# ESP32-S31 register map
Vendor: ESPRESSIF SYSTEMS (SHANGHAI) CO., LTD.; Series: ESP32 S-Series; File version: 1
CPU: RV32IMAFC r0p0, little endian, no MPU, FPU, 0 interrupt priority bits
Address unit: 32 bits
Registers are 32-bit, read-write, reset 0x0 unless marked. A register's access mark holds for its fields unless they carry their own. Offsets are from the block's base; [hi:lo] are bit positions.

## GMAC (part 4 of 6) — GMAC Peripheral
Base 0x20350000
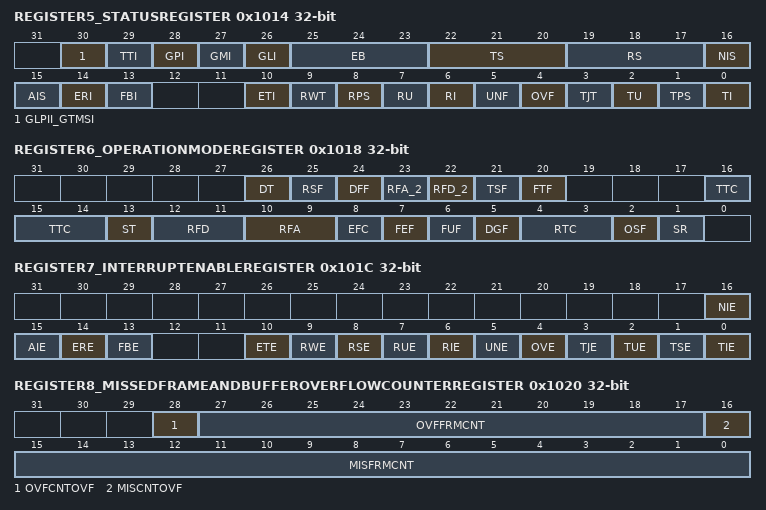
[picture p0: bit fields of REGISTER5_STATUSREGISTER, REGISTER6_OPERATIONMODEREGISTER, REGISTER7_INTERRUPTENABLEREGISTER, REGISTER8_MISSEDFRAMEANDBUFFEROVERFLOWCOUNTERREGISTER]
0x1014 REGISTER5_STATUSREGISTER access per field — The Software driver _application_ reads this register during interrupt service routine or polling to determine the status of the DMA
  [30] GLPII_GTMSI ro — GLPII: GMAC LPI Interrupt This bit indicates an interrupt event in the LPI logic of the MAC To reset this bit to 1'b0, the software must read the corresponding registers in the DWC_gmac to get the exact cause of the interrupt and clear its source Note: GLPII status is given only in Channel 0 DMA register and is applicable only when the Energy Efficient Ethernet feature is enabled Otherwise, this bit is reserved When this bit is high, the interrupt signal from the MAC _sbd_intr_o_ is high
  [29] TTI ro — Timestamp Trigger Interrupt This bit indicates an interrupt event in the Timestamp Generator block of the DWC_gmac The software must read the corresponding registers in the DWC_gmac to get the exact cause of the interrupt and clear its source to reset this bit to 1'b0 When this bit is high, the interrupt signal from the DWC_gmac subsystem _sbd_intr_o_ is high This bit is applicable only when the IEEE 1588 Timestamp feature is enabled Otherwise, this bit is reserved
  [28] GPI ro — GMAC PMT Interrupt This bit indicates an interrupt event in the PMT module of the DWC_gmac The software must read the PMT Control and Status Register in the MAC to get the exact cause of interrupt and clear its source to reset this bit to 1’b0 The interrupt signal from the DWC_gmac subsystem _sbd_intr_o_ is high when this bit is high This bit is applicable only when the Power Management feature is enabled Otherwise, this bit is reserved Note: The GPI and pmt_intr_o interrupts are generated in different clock domains
  [27] GMI ro — GMAC MMC Interrupt This bit reflects an interrupt event in the MMC module of the DWC_gmac The software must read the corresponding registers in the DWC_gmac to get the exact cause of the interrupt and clear the source of interrupt to make this bit as 1’b0 The interrupt signal from the DWC_gmac subsystem _sbd_intr_o_ is high when this bit is high This bit is applicable only when the MAC Management Counters _MMC_ are enabled Otherwise, this bit is reserved
  [26] GLI ro — GMAC Line Interface Interrupt When set, this bit reflects any of the following interrupt events in the DWC_gmac interfaces _if present and enabled in your configuration_: PCS _TBI, RTBI, or SGMII_: Link change or autonegotiation complete event SMII or RGMII: Link change event General Purpose Input Status _GPIS_: Any LL or LH event on the gpi_i input ports To identify the exact cause of the interrupt, the software must first read Bit 11 and Bits[2:0] of Register 14 _Interrupt Status Register_ and then to clear the source of interrupt _which also clears the GLI interrupt_, read any of the following corresponding registers: PCS _TBI, RTBI, or SGMII_: Register 49 _AN Status Register_ SMII or RGMII: Register 54 _SGMII/RGMII/SMII Control and Status Register_ General Purpose Input _GPI_: Register 56 _General Purpose IO Register_ The interrupt signal from the DWC_gmac subsystem _sbd_intr_o_ is high when this bit is high
  [25:23] EB ro — Error Bits This field indicates the type of error that caused a Bus Error, for example, error response on the AHB or AXI interface This field is valid only when Bit 13 _FBI_ is set This field does not generate an interrupt 0 0 0: Error during Rx DMA Write Data Transfer 0 1 1: Error during Tx DMA Read Data Transfer 1 0 0: Error during Rx DMA Descriptor Write Access 1 0 1: Error during Tx DMA Descriptor Write Access 1 1 0: Error during Rx DMA Descriptor Read Access 1 1 1: Error during Tx DMA Descriptor Read Access Note: 001 and 010 are reserved
  [22:20] TS ro — Transmit Process State This field indicates the Transmit DMA FSM state This field does not generate an interrupt 3’b000: Stopped: Reset or Stop Transmit Command issued 3’b001: Running: Fetching Transmit Transfer Descriptor 3’b010: Running: Waiting for status 3’b011: Running: Reading Data from host memory buffer and queuing it to transmit buffer _Tx FIFO_ 3’b100: TIME_STAMP write state 3’b101: Reserved for future use 3’b110: Suspended: Transmit Descriptor Unavailable or Transmit Buffer Underflow 3’b111: Running: Closing Transmit Descriptor
  [19:17] RS ro — Receive Process State This field indicates the Receive DMA FSM state This field does not generate an interrupt 3’b000: Stopped: Reset or Stop Receive Command issued 3’b001: Running: Fetching Receive Transfer Descriptor 3’b010: Reserved for future use 3’b011: Running: Waiting for receive packet 3’b100: Suspended: Receive Descriptor Unavailable 3’b101: Running: Closing Receive Descriptor 3’b110: TIME_STAMP write state 3’b111: Running: Transferring the receive packet data from receive buffer to host memory
  [16] NIS rw — Normal Interrupt Summary Normal Interrupt Summary bit value is the logical OR of the following bits when the corresponding interrupt bits are enabled in Register 7 _Interrupt Enable Register_: Register 5[0]: Transmit Interrupt Register 5[2]: Transmit Buffer Unavailable Register 5[6]: Receive Interrupt Register 5[14]: Early Receive Interrupt Only unmasked bits _interrupts for which interrupt enable is set in Register 7_ affect the Normal Interrupt Summary bit This is a sticky bit and must be cleared _by writing 1 to this bit_ each time a corresponding bit, which causes NIS to be set, is cleared
  [15] AIS rw — Abnormal Interrupt Summary Abnormal Interrupt Summary bit value is the logical OR of the following when the corresponding interrupt bits are enabled in Register 7 _Interrupt Enable Register_: Register 5[1]: Transmit Process Stopped Register 5[3]: Transmit Jabber Timeout Register 5[4]: Receive FIFO Overflow Register 5[5]: Transmit Underflow Register 5[7]: Receive Buffer Unavailable Register 5[8]: Receive Process Stopped Register 5[9]: Receive Watchdog Timeout Register 5[10]: Early Transmit Interrupt Register 5[13]: Fatal Bus Error Only unmasked bits affect the Abnormal Interrupt Summary bit This is a sticky bit and must be cleared _by writing 1 to this bit_ each time a corresponding bit, which causes AIS to be set, is cleared
  [14] ERI rw — Early Receive Interrupt This bit indicates that the DMA filled the first data buffer of the packet This bit is cleared when the software writes 1 to this bit or Bit 6 _RI_ of this register is set _whichever occurs earlier_
  [13] FBI rw — Fatal Bus Error Interrupt This bit indicates that a bus error occurred, as described in Bits [25:23] When this bit is set, the corresponding DMA engine disables all of its bus accesses 12:11 Reserved 00 RO
  [10] ETI rw — Early Transmit Interrupt This bit indicates that the frame to be transmitted is fully transferred to the MTL Transmit FIFO
  [9] RWT rw — Receive Watchdog Timeout When set, this bit indicates that the Receive Watchdog Timer expired while receiving the current frame and the current frame is truncated after the watchdog timeout
  [8] RPS rw — Receive Process Stopped This bit is asserted when the Receive Process enters the Stopped state
  [7] RU rw — Receive Buffer Unavailable This bit indicates that the host owns the Next Descriptor in the Receive List and the DMA cannot acquire it The Receive Process is suspended To resume processing Receive descriptors, the host should change the ownership of the descriptor and issue a Receive Poll Demand command If no Receive Poll Demand is issued, the Receive Process resumes when the next recognized incoming frame is received This bit is set only when the previous Receive Descriptor is owned by the DMA
  [6] RI rw — Receive Interrupt This bit indicates that the frame reception is complete When reception is complete, the Bit 31 of RDES1 _Disable Interrupt on Completion_ is reset in the last Descriptor, and the specific frame status information is updated in the descriptor The reception remains in the Running state
  [5] UNF rw — Transmit Underflow This bit indicates that the Transmit Buffer had an Underflow during frame transmission Transmission is suspended and an Underflow Error TDES0[1] is set
  [4] OVF rw — Receive Overflow This bit indicates that the Receive Buffer had an Overflow during frame reception If the partial frame is transferred to the application, the overflow status is set in RDES0[11]
  [3] TJT rw — Transmit Jabber Timeout This bit indicates that the Transmit Jabber Timer expired, which happens when the frame size exceeds 2,048 _10,240 bytes when the Jumbo frame is enabled_ When the Jabber Timeout occurs, the transmission process is aborted and placed in the Stopped state This causes the Transmit Jabber Timeout TDES0[14] flag to assert
  [2] TU rw — Transmit Buffer Unavailable This bit indicates that the host owns the Next Descriptor in the Transmit List and the DMA cannot acquire it Transmission is suspended Bits[22:20] explain the Transmit Process state transitions To resume processing Transmit descriptors, the host should change the ownership of the descriptor by setting TDES0[31] and then issue a Transmit Poll Demand command
  [1] TPS rw — Transmit Process Stopped This bit is set when the transmission is stopped
  [0] TI rw — Transmit Interrupt This bit indicates that the frame transmission is complete When transmission is complete, Bit 31 _OWN_ of TDES0 is reset, and the specific frame status information is updated in the descriptor
0x1018 REGISTER6_OPERATIONMODEREGISTER — Establishes the Receive and Transmit operating modes and command Note: This register is valid and present in the GMACMTL configuration
  [26] DT — Disable Dropping of TCP/IP Checksum Error Frames When this bit is set, the MAC does not drop the frames which only have errors detected by the Receive Checksum Offload engine Such frames do not have any errors _including FCS error_ in the Ethernet frame received by the MAC but have errors only in the encapsulated payload When this bit is reset, all error frames are dropped if the FEF bit is reset If the IPC Full Checksum Offload Engine _Type 2_ is disabled, this bit is reserved _RO with value 1'b0_
  [25] RSF — Receive Store and Forward When this bit is set, the MTL reads a frame from the Rx FIFO only after the complete frame has been written to it, ignoring the RTC bits When this bit is reset, the Rx FIFO operates in the cutthrough mode, subject to the threshold specified by the RTC bits
  [24] DFF — Disable Flushing of Received Frames When this bit is set, the Rx DMA does not flush any frames because of the unavailability of receive descriptors or buffers as it does normally when this bit is reset _See “Receive Process Suspended” on page 83_ This bit is reserved _and RO_ in the GMACMTL configuration
  [23] RFA_2 — MSB of Threshold for Activating Flow Control If the DWC_gmac is configured for an Rx FIFO size of 8 KB or more, this bit _when set_ provides additional threshold levels for activating the flow control in both half duplex and fullduplex modes This bit _as Most Significant Bit_, along with the RFA _Bits [10:9]_, gives the following thresholds for activating flow control: 100: Full minus 5 KB, that is, FULL — 5 KB 101: Full minus 6 KB, that is, FULL — 6 KB 110: Full minus 7 KB, that is, FULL — 7 KB 111: Reserved This bit is reserved _and RO_ if the Rx FIFO is 4 KB or less deep
  [22] RFD_2 — MSB of Threshold for Deactivating Flow Control If the DWC_gmac is configured for Rx FIFO size of 8 KB or more, this bit _when set_ provides additional threshold levels for deactivating the flow control in both halfduplex and fullduplex modes This bit _as Most Significant Bit_ along with the RFD _Bits [12:11]_ gives the following thresholds for deactivating flow control: 100: Full minus 5 KB, that is, FULL — 5 KB 101: Full minus 6 KB, that is, FULL — 6 KB 110: Full minus 7 KB, that is, FULL — 7 KB 111: Reserved This bit is reserved _and RO_ if the Rx FIFO is 4 KB or less deep
  [21] TSF — Transmit Store and Forward When this bit is set, transmission starts when a full frame resides in the MTL Transmit FIFO When this bit is set, the TTC values specified in Bits [16:14] are ignored This bit should be changed only when the transmission is stopped
  [20] FTF — Flush Transmit FIFO When this bit is set, the transmit FIFO controller logic is reset to its default values and thus all data in the Tx FIFO is lost or flushed This bit is cleared internally when the flushing operation is complete The Operation Mode register should not be written to until this bit is cleared The data which is already accepted by the MAC transmitter is not flushed It is scheduled for transmission and results in underflow and runt frame transmission Note: The flush operation is complete only when the Tx FIFO is emptied of its contents and all the pending Transmit Status of the transmitted frames are accepted by the host In order to complete this flush operation, the PHY transmit clock _clk_tx_i_ is required to be active 19:17 Reserved 000 RO
  [16:14] TTC — Transmit Threshold Control These bits control the threshold level of the MTL Transmit FIFO Transmission starts when the frame size within the MTL Transmit FIFO is larger than the threshold In addition, full frames with a length less than the threshold are also transmitted These bits are used only when Bit 21 _TSF_ is reset 000: 64 001: 128 010: 192 011: 256 100: 40 101: 32 110: 24 111: 16
  [13] ST — Start or Stop Transmission Command When this bit is set, transmission is placed in the Running state, and the DMA checks the Transmit List at the current position for a frame to be transmitted Descriptor acquisition is attempted either from the current position in the list, which is the Transmit List Base Address set by Register 4 _Transmit Descriptor List Address Register_, or from the position retained when transmission was stopped previously If the DMA does not own the current descriptor, transmission enters the Suspended state and Bit 2 _Transmit Buffer Unavailable_ of Register 5 _Status Register_ is set The Start Transmission command is effective only when transmission is stopped If the command is issued before setting Register 4 _Transmit Descriptor List Address Register_, then the DMA behavior is unpredictable When this bit is reset, the transmission process is placed in the Stopped state after completing the transmission of the current frame The Next Descriptor position in the Transmit List is saved, and it becomes the current position when transmission is restarted To change the list address, you need to program Register 4 _Transmit Descriptor List Address Register_ with a new value when this bit is reset The new value is considered when this bit is set again The stop transmission command is effective only when the transmission of the current frame is complete or the transmission is in the Suspended state Note: For information about how to pause the transmission, see “Stopping and Starting Transmission” on page 715
  [12:11] RFD — Threshold for Deactivating Flow Control _in halfduplex and fullduplex modes_ These bits control the threshold _Filllevel of Rx FIFO_ at which the flow control is deasserted after activation 00: Full minus 1 KB, that is, FULL — 1 KB 01: Full minus 2 KB, that is, FULL — 2 KB 10: Full minus 3 KB, that is, FULL — 3 KB 11: Full minus 4 KB, that is, FULL — 4 KB The deassertion is effective only after flow control is asserted If the Rx FIFO is 8 KB or more, an additional Bit _RFD_2_ is used for more threshold levels as described in Bit 22 These bits are reserved and readonly when the Rx FIFO depth is less than 4 KB Note: For proper flow control, the value programmed in the “RFD_2, RFD” fields should be equal to or more than the value programmed in the “RFA_2, RFA” fields
  [10:9] RFA — Threshold for Activating Flow Control _in halfduplex and fullduplex modes_ These bits control the threshold _Fill level of Rx FIFO_ at which the flow control is activated 00: Full minus 1 KB, that is, FULL—1KB 01: Full minus 2 KB, that is, FULL—2KB 10: Full minus 3 KB, that is, FULL—3KB 11: Full minus 4 KB, that is, FULL—4KB These values are applicable only to Rx FIFOs of 4 KB or more and when Bit 8 _EFC_ is set high If the Rx FIFO is 8 KB or more, an additional Bit _RFA_2_ is used for more threshold levels as described in Bit 23 These bits are reserved and readonly when the depth of Rx FIFO is less than 4 KB Note: When FIFO size is exactly 4 KB, although the DWC_gmac allows you to program the value of these bits to 11, the software should not program these bits to 2'b11 The value 2'b11 means flow control on FIFO empty condition
  [8] EFC — Enable HW Flow Control When this bit is set, the flow control signal operation based on the filllevel of Rx FIFO is enabled When reset, the flow control operation is disabled This bit is not used _reserved and always reset_ when the Rx FIFO is less than 4 KB
  [7] FEF — Forward Error Frames When this bit is reset, the Rx FIFO drops frames with error status _CRC error, collision error, GMII_ER, giant frame, watchdog timeout, or overflow_ However, if the start byte _write_ pointer of a frame is already transferred to the read controller side _in Threshold mode_, then the frame is not dropped In the GMACMTL configuration in which the Frame Length FIFO is also enabled during core configuration, the Rx FIFO drops the error frames if that frame's start byte is not transferred _output_ on the ARI bus When the FEF bit is set, all frames except runt error frames are forwarded to the DMA If the Bit 25 _RSF_ is set and the Rx FIFO overflows when a partial frame is written, then the frame is dropped irrespective of the FEF bit setting However, if the Bit 25 _RSF_ is reset and the Rx FIFO overflows when a partial frame is written, then a partial frame may be forwarded to the DMA Note: When FEF bit is reset, the giant frames are dropped if the giant frame status is given in Rx Status _in Table 86 or Table 823_ in the following configurations: The IP checksum engine _Type 1_ and full checksum offload engine _Type 2_ are not selected The advanced timestamp feature is not selected but the extended status is selected The extended status is available with the following features: L3L4 filter in GMACCORE or GMACMTL configurations Full checksum offload engine _Type 2_ with enhanced descriptor format in the GMACDMA, GMACAHB, or GMACAXI configurations
  [6] FUF — Forward Undersized Good Frames When set, the Rx FIFO forwards Undersized frames _that is, frames with no Error and length less than 64 bytes_ including padbytes and CRC When reset, the Rx FIFO drops all frames of less than 64 bytes, unless a frame is already transferred because of the lower value of Receive Threshold, for example, RTC = 01
  [5] DGF — Drop Giant Frames When set, the MAC drops the received giant frames in the Rx FIFO, that is, frames that are larger than the computed giant frame limit When reset, the MAC does not drop the giant frames in the Rx FIFO Note: This bit is available in the following configurations in which the giant frame status is not provided in Rx status and giant frames are not dropped by default: Configurations in which IP Checksum Offload _Type 1_ is selected in Rx Configurations in which the IPC Full Checksum Offload Engine _Type 2_ is selected in Rx with normal descriptor format Configurations in which the Advanced Timestamp feature is selected In all other configurations, this bit is not used _reserved and always reset_
  [4:3] RTC — Receive Threshold Control These two bits control the threshold level of the MTL Receive FIFO Transfer _request_ to DMA starts when the frame size within the MTL Receive FIFO is larger than the threshold In addition, full frames with length less than the threshold are automatically transferred The value of 11 is not applicable if the configured Receive FIFO size is 128 bytes These bits are valid only when the RSF bit is zero, and are ignored when the RSF bit is set to 1 00: 64 01: 32 10: 96 11: 128
  [2] OSF — Operate on Second Frame When this bit is set, it instructs the DMA to process the second frame of the Transmit data even before the status for the first frame is obtained
  [1] SR — Start or Stop Receive When this bit is set, the Receive process is placed in the Running state The DMA attempts to acquire the descriptor from the Receive list and processes the incoming frames The descriptor acquisition is attempted from the current position in the list, which is the address set by the Register 3 _Receive Descriptor List Address Register_ or the position retained when the Receive process was previously stopped If the DMA does not own the descriptor, reception is suspended and Bit 7 _Receive Buffer Unavailable_ of Register 5 _Status Register_ is set The Start Receive command is effective only when the reception has stopped If the command is issued before setting Register 3 _Receive Descriptor List Address Register_, the DMA behavior is unpredictable When this bit is cleared, the Rx DMA operation is stopped after the transfer of the current frame The next descriptor position in the Receive list is saved and becomes the current position after the Receive process is restarted The Stop Receive command is effective only when the Receive process is in either the Running _waiting for receive packet_ or in the Suspended state Note: For information about how to pause the transmission, see “Stopping and Starting Transmission” on page 715
0x101C REGISTER7_INTERRUPTENABLEREGISTER — Enables the interrupts reported by the Status Register
  [16] NIE — Normal Interrupt Summary Enable When this bit is set, normal interrupt summary is enabled When this bit is reset, normal interrupt summary is disabled This bit enables the following interrupts in Register 5 _Status Register_: Register 5[0]: Transmit Interrupt Register 5[2]: Transmit Buffer Unavailable Register 5[6]: Receive Interrupt Register 5[14]: Early Receive Interrupt
  [15] AIE — Abnormal Interrupt Summary Enable When this bit is set, abnormal interrupt summary is enabled When this bit is reset, the abnormal interrupt summary is disabled This bit enables the following interrupts in Register 5 _Status Register_: Register 5[1]: Transmit Process Stopped Register 5[3]: Transmit Jabber Timeout Register 5[4]: Receive Overflow Register 5[5]: Transmit Underflow Register 5[7]: Receive Buffer Unavailable Register 5[8]: Receive Process Stopped Register 5[9]: Receive Watchdog Timeout Register 5[10]: Early Transmit Interrupt Register 5[13]: Fatal Bus Error
  [14] ERE — Early Receive Interrupt Enable When this bit is set with Normal Interrupt Summary Enable _Bit 16_, the Early Receive Interrupt is enabled When this bit is reset, the Early Receive Interrupt is disabled
  [13] FBE — Fatal Bus Error Enable When this bit is set with Abnormal Interrupt Summary Enable _Bit 15_, the Fatal Bus Error Interrupt is enabled When this bit is reset, the Fatal Bus Error Enable Interrupt is disabled 12:11 Reserved 00 RO
  [10] ETE — Early Transmit Interrupt Enable When this bit is set with an Abnormal Interrupt Summary Enable _Bit 15_, the Early Transmit Interrupt is enabled When this bit is reset, the Early Transmit Interrupt is disabled
  [9] RWE — Receive Watchdog Timeout Enable When this bit is set with Abnormal Interrupt Summary Enable _Bit 15_, the Receive Watchdog Timeout Interrupt is enabled When this bit is reset, the Receive Watchdog Timeout Interrupt is disabled
  [8] RSE — Receive Stopped Enable When this bit is set with Abnormal Interrupt Summary Enable _Bit 15_, the Receive Stopped Interrupt is enabled When this bit is reset, the Receive Stopped Interrupt is disabled
  [7] RUE — Receive Buffer Unavailable Enable When this bit is set with Abnormal Interrupt Summary Enable _Bit 15_, the Receive Buffer Unavailable Interrupt is enabled When this bit is reset, the Receive Buffer Unavailable Interrupt is disabled
  [6] RIE — Receive Interrupt Enable When this bit is set with Normal Interrupt Summary Enable _Bit 16_, the Receive Interrupt is enabled When this bit is reset, the Receive Interrupt is disabled
  [5] UNE — Underflow Interrupt Enable When this bit is set with Abnormal Interrupt Summary Enable _Bit 15_, the Transmit Underflow Interrupt is enabled When this bit is reset, the Underflow Interrupt is disabled
  [4] OVE — Overflow Interrupt Enable When this bit is set with Abnormal Interrupt Summary Enable _Bit 15_, the Receive Overflow Interrupt is enabled When this bit is reset, the Overflow Interrupt is disabled
  [3] TJE — Transmit Jabber Timeout Enable When this bit is set with Abnormal Interrupt Summary Enable _Bit 15_, the Transmit Jabber Timeout Interrupt is enabled When this bit is reset, the Transmit Jabber Timeout Interrupt is disabled
  [2] TUE — Transmit Buffer Unavailable Enable When this bit is set with Normal Interrupt Summary Enable _Bit 16_, the Transmit Buffer Unavailable Interrupt is enabled When this bit is reset, the Transmit Buffer Unavailable Interrupt is disabled
  [1] TSE — Transmit Stopped Enable When this bit is set with Abnormal Interrupt Summary Enable _Bit 15_, the Transmission Stopped Interrupt is enabled When this bit is reset, the Transmission Stopped Interrupt is disabled
  [0] TIE — Transmit Interrupt Enable When this bit is set with Normal Interrupt Summary Enable _Bit 16_, the Transmit Interrupt is enabled When this bit is reset, the Transmit Interrupt is disabled The sbd_intr_o interrupt is generated as shown in Figure 61 It is asserted only when the TTI, GPI, GMI, GLI, or GLPII bit of the DMA Status register is asserted, or when the NIS or AIS Status bit is asserted and the corresponding Interrupt Enable bits _NIE or AIE_ are enabled
0x1020 REGISTER8_MISSEDFRAMEANDBUFFEROVERFLOWCOUNTERREGISTER — Contains the counters for discarded frames because no host Receive Descriptor was available or because of Receive FIFO Overflow
  [28] OVFCNTOVF — Overflow Bit for FIFO Overflow Counter This bit is set every time the Overflow Frame Counter _Bits[27:17]_ overflows, that is, the Rx FIFO overflows with the overflow frame counter at maximum value In such a scenario, the overflow frame counter is reset to allzeros and this bit indicates that the rollover happened
  [27:17] OVFFRMCNT — Overflow Frame Counter This field indicates the number of frames missed by the application This counter is incremented each time the MTL FIFO overflows The counter is cleared when this register is read with mci_be_i[2] at 1’b1
  [16] MISCNTOVF — Overflow Bit for Missed Frame Counter This bit is set every time Missed Frame Counter _Bits[15:0]_ overflows, that is, the DMA discards an incoming frame because of the Host Receive Buffer being unavailable with the missed frame counter at maximum value In such a scenario, the Missed frame counter is reset to allzeros and this bit indicates that the rollover happened
  [15:0] MISFRMCNT — Missed Frame Counter This field indicates the number of frames missed by the controller because of the Host Receive Buffer being unavailable This counter is incremented each time the DMA discards an incoming frame The counter is cleared when this register is read with mci_be_i[0] at 1’b1
0x1024 REGISTER9_RECEIVEINTERRUPTWATCHDOGTIMERREGISTER — Watchdog timeout for Receive Interrupt _RI_ from DMA
  [7:0] RIWT — RI Watchdog Timer Count This bit indicates the number of system clock cycles multiplied by 256 for which the watchdog timer is set The watchdog timer gets triggered with the programmed value after the Rx DMA completes the transfer of a frame for which the RI status bit is not set because of the setting in the corresponding descriptor RDES1[31] When the watchdog timer runs out, the RI bit is set and the timer is stopped The watchdog timer is reset when the RI bit is set high because of automatic setting of RI as per RDES1[31] of any received frame
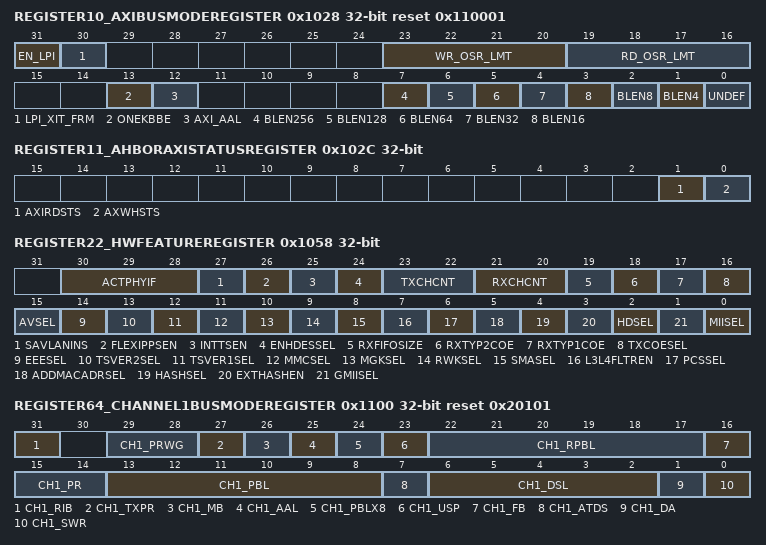
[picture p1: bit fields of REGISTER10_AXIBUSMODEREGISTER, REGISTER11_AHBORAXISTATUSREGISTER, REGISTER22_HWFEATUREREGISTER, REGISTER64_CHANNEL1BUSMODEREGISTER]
0x1028 REGISTER10_AXIBUSMODEREGISTER access per field reset 0x110001 — Controls AXI master behavior _mainly controls burst splitting and number of outstanding requests_
  [31] EN_LPI rw — Enable Low Power Interface _LPI_ When set to 1, this bit enables the LPI mode supported by the GMACAXI configuration and accepts the LPI request from the AXI System Clock controller When set to 0, this bit disables the LPI mode and always denies the LPI request from the AXI System Clock controller
  [30] LPI_XIT_FRM rw — Unlock on Magic Packet or Remote WakeUp Frame When set to 1, this bit enables the GMACAXI to come out of the LPI mode only when the magic packet or remote wakeup frame is received When set to 0, this bit enables the GMACAXI to come out of LPI mode when any frame is received 29:24 Reserved 00H RO
  [23:20] WR_OSR_LMT rw — AXI Maximum Write Outstanding Request Limit This value limits the maximum outstanding request on the AXI write interface Maximum outstanding requests = WR_OSR_LMT+1 Note: Bit 22 is reserved if AXI_GM_MAX_WR_REQUESTS = 4 Bit 23 bit is reserved if AXI_GM_MAX_WR_REQUESTS != 16
  [19:16] RD_OSR_LMT rw — AXI Maximum Read Outstanding Request Limit This value limits the maximum outstanding request on the AXI read interface Maximum outstanding requests = RD_OSR_LMT+1 Note: Bit 18 is reserved if AXI_GM_MAX_RD_REQUESTS = 4 Bit 19 is reserved if AXI_GM_MAX_RD_REQUESTS != 16 15:14 Reserved 00 RO
  [13] ONEKBBE rw — 1 KB Boundary Crossing Enable for the GMACAXI Master When set, the GMACAXI master performs burst transfers that do not cross 1 KB boundary When reset, the GMACAXI master performs burst transfers that do not cross 4 KB boundary
  [12] AXI_AAL ro — AddressAligned Beats This bit is readonly bit and reflects the Bit 25 _AAL_ of Register 0 _Bus Mode Register_ When this bit is set to 1, the GMACAXI performs addressaligned burst transfers on both read and write channels 11:8 Reserved 0H RO
  [7] BLEN256 rw — AXI Burst Length 256 When this bit is set to 1, the GMACAXI is allowed to select a burst length of 256 on the AXI master interface This bit is present only when the configuration parameter AXI_BL is set to 256 Otherwise, this bit is reserved and is readonly _RO_
  [6] BLEN128 rw — AXI Burst Length 128 When this bit is set to 1, the GMACAXI is allowed to select a burst length of 128 on the AXI master interface This bit is present only when the configuration parameter AXI_BL is set to 128 or more Otherwise, this bit is reserved and is readonly _RO_
  [5] BLEN64 rw — AXI Burst Length 64 When this bit is set to 1, the GMACAXI is allowed to select a burst length of 64 on the AXI master interface This bit is present only when the configuration parameter AXI_BL is set to 64 or more Otherwise, this bit is reserved and is readonly _RO_
  [4] BLEN32 rw — AXI Burst Length 32 When this bit is set to 1, the GMACAXI is allowed to select a burst length of 32 on the AXI master interface This bit is present only when the configuration parameter AXI_BL is set to 32 or more Otherwise, this bit is reserved and is readonly _RO_
  [3] BLEN16 rw — AXI Burst Length 16 When this bit is set to 1 or UNDEF is set to 1, the GMACAXI is allowed to select a burst length of 16 on the AXI master interface
  [2] BLEN8 rw — AXI Burst Length 8 When this bit is set to 1, the GMACAXI is allowed to select a burst length of 8 on the AXI master interface Setting this bit has no effect when UNDEF is set to 1
  [1] BLEN4 rw — AXI Burst Length 4 When this bit is set to 1, the GMACAXI is allowed to select a burst length of 4 on the AXI master interface Setting this bit has no effect when UNDEF is set to 1
  [0] UNDEF ro — AXI Undefined Burst Length This bit is readonly bit and indicates the complement _invert_ value of Bit 16 _FB_ in Register 0 _Bus Mode Register_ When this bit is set to 1, the GMACAXI is allowed to perform any burst length equal to or below the maximum allowed burst length programmed in Bits[7:3] When this bit is set to 0, the GMACAXI is allowed to perform only fixed burst lengths as indicated by BLEN256, BLEN128, BLEN64, BLEN32, BLEN16, BLEN8, or BLEN4, or a burst length of 1 If UNDEF is set and none of the BLEN bits is set, then GMACAXI is allowed to perform a burst length of 16
0x102C REGISTER11_AHBORAXISTATUSREGISTER ro — Gives the idle status of the AHB master interface in the GMACAHB configuration Gives the idle status of the AXI master's read or write channel in the GMACAXI configuration
  [1] AXIRDSTS — AXI Master Read Channel Status When high, it indicates that AXI master's read channel is active and transferring data
  [0] AXWHSTS — AXI Master Write Channel or AHB Master Status When high, it indicates that AXI master's write channel is active and transferring data in the GMACAXI configuration In the GMACAHB configuration, it indicates that the AHB master interface FSMs are in the nonidle state
0x1048 REGISTER18_CURRENTHOSTTRANSMITDESCRIPTORREGISTER ro — Points to the start of current Transmit Descriptor read by the DMA
  [31:0] CURTDESAPTR — Host Transmit Descriptor Address Pointer
0x104C REGISTER19_CURRENTHOSTRECEIVEDESCRIPTORREGISTER ro — Points to the start of current Receive Descriptor read by the DMA
  [31:0] CURRDESAPTR — Host Receive Descriptor Address Pointer
0x1050 REGISTER20_CURRENTHOSTTRANSMITBUFFERADDRESSREGISTER ro — Points to the current Transmit Buffer address read by the DMA
  [31:0] CURTBUFAPTR — Host Transmit Buffer Address Pointer
0x1054 REGISTER21_CURRENTHOSTRECEIVEBUFFERADDRESSREGISTER ro — Points to the current Receive Buffer address read by the DMA
  [31:0] CURRBUFAPTR — Host Receive Buffer Address Pointer
0x1058 REGISTER22_HWFEATUREREGISTER ro — Indicates the presence of the optional features of the core
  [30:28] ACTPHYIF — Active or selected PHY interface When you have multiple PHY interfaces in your configuration, this field indicates the sampled value of phy_intf_sel_i during reset deassertion 000: GMII or MII 001: RGMII 010: SGMII 011: TBI 100: RMII 101: RTBI 110: SMII 111: RevMII All Others: Reserved
  [27] SAVLANINS — Source Address or VLAN Insertion
  [26] FLEXIPPSEN — Flexible PulsePerSecond Output
  [25] INTTSEN — Timestamping with Internal System Time
  [24] ENHDESSEL — Alternate _Enhanced Descriptor_
  [23:22] TXCHCNT — Number of additional Tx Channels
  [21:20] RXCHCNT — Number of additional Rx Channels
  [19] RXFIFOSIZE — Rx FIFO > 2,048 Bytes
  [18] RXTYP2COE — IP Checksum Offload _Type 2_ in Rx
  [17] RXTYP1COE — IP Checksum Offload _Type 1_ in Rx Note: If IPCHKSUM_EN = Enabled and IPC_FULL_OFFLOAD = Enabled, then RXTYP1COE = 0 and RXTYP2COE = 1
  [16] TXCOESEL — Checksum Offload in Tx
  [15] AVSEL — AV feature
  [14] EEESEL — Energy Efficient Ethernet
  [13] TSVER2SEL — IEEE 15882008 Advanced timestamp
  [12] TSVER1SEL — Only IEEE 15882002 timestamp
  [11] MMCSEL — RMON module
  [10] MGKSEL — PMT magic packet
  [9] RWKSEL — PMT remote wakeup frame
  [8] SMASEL — SMA _MDIO_ Interface
  [7] L3L4FLTREN — Layer 3 and Layer 4 feature
  [6] PCSSEL — PCS registers _TBI, SGMII, or RTBI PHY interface_
  [5] ADDMACADRSEL — Multiple MAC Address registers
  [4] HASHSEL — HASH filter
  [3] EXTHASHEN — Expanded DA Hash filter
  [2] HDSEL — Halfduplex support
  [1] GMIISEL — 1000 Mbps support
  [0] MIISEL — 10 or 100 Mbps support
0x1100 REGISTER64_CHANNEL1BUSMODEREGISTER reset 0x20101 — Controls the Host Interface mode for Channel 1
  [31] CH1_RIB — Rebuild INCRx Burst When this bit is set high and the AHB master gets an EBT _Retry, Split, or Losing bus grant_, the AHB master interface rebuilds the pending beats of any burst transfer initiated with INCRx The AHB master interface rebuilds the beats with a combination of specified bursts with INCRx and SINGLE By default, the AHB master interface rebuilds pending beats of an EBT with an unspecified _INCR_ burst This bit is valid only in the GMACAHB configuration It is reserved in all other configuration
  [29:28] CH1_PRWG — Channel Priority Weights This field sets the priority weights for Channel 1 during the roundrobin arbitration between the DMA channels for the system bus 00: The priority weight is 1 01: The priority weight is 2 10: The priority weight is 3 11: The priority weight is 4 This field is present in all DWC_gmac configurations except GMACAXI when you select the AV feature Otherwise, this field is reserved and readonly _RO_ For more information about the priority weights of DMA channels, see “DMA Arbiter Functions” on page 167
  [27] CH1_TXPR — Transmit Priority When set, this bit indicates that the transmit DMA has higher priority than the receive DMA during arbitration for the systemside bus In the GMACAXI configuration, this bit is reserved and readonly _RO_ For more information about the priority scheme between the transmit and receive paths, see Table 412 in “DMA Arbiter Functions” on page 167
  [26] CH1_MB — Mixed Burst When this bit is set high and the FB bit is low, the AHB master interface starts all bursts of length more than 16 with INCR _undefined burst_, whereas it reverts to fixed burst transfers _INCRx and SINGLE_ for burst length of 16 and less This bit is valid only in the GMACAHB configuration and reserved in all other configuration
  [25] CH1_AAL — AddressAligned Beats When this bit is set high and the FB bit is equal to 1, the AHB or AXI interface generates all bursts aligned to the start address LS bits If the FB bit is equal to 0, the first burst _accessing the start address of data buffer_ is not aligned, but subsequent bursts are aligned to the address This bit is valid only in the GMACAHB and GMACAXI configurations and is reserved _RO with default value 0_ in all other configurations
  [24] CH1_PBLX8 — PBLx8 Mode When set high, this bit multiplies the programmed PBL value _Bits [22:17] and Bits[13:8]_ eight times Therefore, the DMA transfers the data in 8, 16, 32, 64, 128, and 256 beats depending on the PBL value Note: This bit function is not backward compatible Before release 350a, this bit was 4xPBL
  [23] CH1_USP — Use Separate PBL When set high, this bit configures the Rx DMA to use the value configured in Bits [22:17] as PBL The PBL value in Bits [13:8] is applicable only to the Tx DMA operations When reset to low, the PBL value in Bits [13:8] is applicable for both DMA engines
  [22:17] CH1_RPBL — Rx DMA PBL This field indicates the maximum number of beats to be transferred in one Rx DMA transaction This is the maximum value that is used in a single block Read or Write The Rx DMA always attempts to burst as specified in the RPBL bit each time it starts a Burst transfer on the host bus You can program RPBL with values of 1, 2, 4, 8, 16, and 32 Any other value results in undefined behavior This field is valid and applicable only when USP is set high
  [16] CH1_FB — Fixed Burst This bit controls whether the AHB or AXI master interface performs fixed burst transfers or not When set, the AHB interface uses only SINGLE, INCR4, INCR8, or INCR16 during start of the normal burst transfers When reset, the AHB or AXI interface uses SINGLE and INCR burst transfer operations For more information, see Bit 0 _UNDEF_ of the AXI Bus Mode register in the GMACAXI configuration
  [15:14] CH1_PR — Priority Ratio These bits control the priority ratio in the weighted roundrobin arbitration between the Rx DMA and Tx DMA These bits are valid only when Bit 1 _DA_ is reset The priority ratio is Rx:Tx or Tx:Rx depending on whether Bit 27 _TXPR_ is reset or set 00: The Priority Ratio is 1:1 01: The Priority Ratio is 2:1 10: The Priority Ratio is 3:1 11: The Priority Ratio is 4:1 In the GMACAXI configuration, these bits are reserved and readonly _RO_ For more information about the priority scheme between the transmit and receive paths, see Table 412 in “DMA Arbiter Functions” on page 167
  [13:8] CH1_PBL — Programmable Burst Length These bits indicate the maximum number of beats to be transferred in one DMA transaction This is the maximum value that is used in a single block Read or Write The DMA always attempts to burst as specified in PBL each time it starts a Burst transfer on the host bus PBL can be programmed with permissible values of 1, 2, 4, 8, 16, and 32 Any other value results in undefined behavior When USP is set high, this PBL value is applicable only for Tx DMA transactions If the number of beats to be transferred is more than 32, then perform the following steps: 1 Set the PBLx8 mode 2 Set the PBL For example, if the maximum number of beats to be transferred is 64, then first set PBLx8 to 1 and then set PBL to 8 The PBL values have the following limitation: The maximum number of possible beats _PBL_ is limited by the size of the Tx FIFO and Rx FIFO in the MTL layer and the data bus width on the DMA The FIFO has a constraint that the maximum beat supported is half the depth of the FIFO, except when specified For different data bus widths and FIFO sizes, the valid PBL range _including x8 mode_ is provided in Table 66 on page 382
  [7] CH1_ATDS — Alternate Descriptor Size When set, the size of the alternate descriptor _described in “Alternate or Enhanced Descriptors” on page 545_ increases to 32 bytes _8 DWORDS_ This is required when the Advanced Timestamp feature or the IPC Full Checksum Offload Engine _Type 2_ is enabled in the receiver The enhanced descriptor is not required if the Advanced Timestamp and IPC Full Checksum Offload Engine _Type 2_ features are not enabled In such case, you can use the 16 bytes descriptor to save 4 bytes of memory This bit is present only when you select the Alternate Descriptor feature and any one of the following features during core configuration: Advanced Timestamp feature IPC Full Checksum Offload Engine _Type 2_ feature Otherwise, this bit is reserved and is readonly When reset, the descriptor size reverts back to 4 DWORDs _16 bytes_ This bit preserves the backward compatibility for the descriptor size In versions prior to 350a, the descriptor size is 16 bytes for both normal and enhanced descriptors In version 350a, descriptor size is increased to 32 bytes because of the Advanced Timestamp and IPC Full Checksum Offload Engine _Type 2_ features
  [6:2] CH1_DSL — Descriptor Skip Length This bit specifies the number of Word, Dword, or Lword _depending on the 32bit, 64bit, or 128bit bus_ to skip between two unchained descriptors The address skipping starts from the end of current descriptor to the start of next descriptor When the DSL value is equal to zero, the descriptor table is taken as contiguous by the DMA in Ring mode
  [1] CH1_DA — DMA Arbitration Scheme This bit specifies the arbitration scheme between the transmit and receive paths of Channel 1 0: Weighted roundrobin with Rx:Tx or Tx:Rx The priority between the paths is according to the priority specified in Bits [15:14] _PR_ and priority weights specified in Bit 27 _TXPR_ 1: Fixed priority The transmit path has priority over receive path when Bit 27 _TXPR_ is set Otherwise, receive path has priority over the transmit path In the GMACAXI configuration, these bits are reserved and are readonly _RO_ For more information about the priority scheme between the transmit and receive paths, see Table 412 in “DMA Arbiter Functions” on page 167
  [0] CH1_SWR — Software Reset When this bit is set, the MAC DMA Controller resets the logic and all internal registers of the MAC It is cleared automatically after the reset operation is complete in all of the DWC_gmac clock domains Before reprogramming any register of the DWC_gmac, you should read a zero _0_ value in this bit Note: The Software reset function is driven only by this bit Bit 0 of Register 64 _Channel 1 Bus Mode Register_ or Register 128 _Channel 2 Bus Mode Register_ has no impact on the Software reset function The reset operation is completed only when all resets in all active clock domains are deasserted Therefore, it is essential that all PHY inputs clocks _applicable for the selected PHY interface_ are present for the software reset completion The time to complete the software reset operation depends on the frequency of the slowest active clock
0x1104 REGISTER65_CHANNEL1TRANSMITPOLLDEMANDREGISTER ro — Used by the host to instruct the DMA to poll the Transmit Descriptor list
  [31:0] CH1_TPD — Transmit Poll Demand When these bits are written with any value, the DMA reads the current descriptor to which the Register 18 _Current Host Transmit Descriptor Register_ is pointing If that descriptor is not available _owned by the Host_, the transmission returns to the Suspend state and Bit 2 _TU_ of Register 5 _Status Register_ is asserted If the descriptor is available, the transmission resumes
0x1108 REGISTER66_CHANNEL1RECEIVEPOLLDEMANDREGISTER ro — Used by the Host to instruct the DMA to poll the Receive Descriptor list
  [31:0] CH1_RPD — Receive Poll Demand When these bits are written with any value, the DMA reads the current descriptor to which the Register 19 _Current Host Receive Descriptor Register_ is pointing If that descriptor is not available _owned by the Host_, the reception returns to the Suspended state and Bit 7 _RU_ of Register 5 _Status Register_ is asserted If the descriptor is available, the Rx DMA returns to the active state
